# TC37XPD register map
Vendor: Infineon; Series: ATVMC; File version: 100
CPU: other r0p0, little endian, MPU, FPU, vendor SysTick, 4 interrupt priority bits
Registers are 32-bit, read-write, reset 0x0 unless marked. A register's access mark holds for its fields unless they carry their own. Offsets are from the block's base; [hi:lo] are bit positions; {n}, {i} and the like mark numbered series; 'fields as' and 'values as' point back to an identical list.

## GETH (part 1 of 7)
Base 0xF001D000
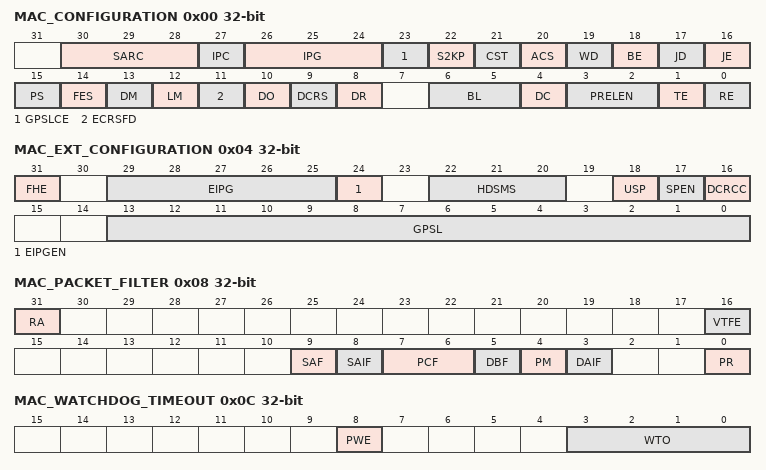
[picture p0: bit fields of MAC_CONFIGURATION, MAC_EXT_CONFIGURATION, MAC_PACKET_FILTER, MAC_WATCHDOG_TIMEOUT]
0x00 MAC_CONFIGURATION — MAC Configuration Register resetvalue={Application Reset:0x0}
  [30:28] SARC — Source Address Insertion or Replacement Control SARC. This field controls the source address insertion or replacement for all transmitted packets. Bit 30 specifies which MAC Address register 0 or 1 is used for source address insertion or replacement based on the values of Bits 29 28 Note Changes to this field take effect only on the start of a packet. If you write to this register field when a packet is being transmitted only the subsequent packet can use the updated value that is the current packet does not use the updated value. Value After Reset 0x0
  [27] IPC — Checksum Offload IPC. When set this bit enables the IPv4 header checksum checking and IPv4 or IPv6 TCP UDP or ICMP payload checksum checking. When this bit is reset the COE function in the receiver is disabled. The Layer 3 and Layer 4 Packet Filter and Enable Split Header features automatically selects the IPC Full Checksum Offload Engine on the Receive side. When any of these features are enabled you must set the IPC bit. Value After Reset 0x0
  [26:24] IPG — Inter Packet Gap IPG. These bits control the minimum IPG between packets during transmission. LOST SEQUENCE DEFINITION This range of minimum IPG is valid in full duplex mode. In the half duplex mode the minimum IPG can be configured only for 64 bit times IPG 100 . Lower values are not considered. When a JAM pattern is being transmitted because of backpressure activation the MAC does not consider the minimum IPG. The above function IPG less than 96 bit times is valid only when EIPGEN bit in MAC Ext Configuration register is reset. When EIPGEN is set then the minimum IPG greater than 96 bit times is controlled as per the description given in EIPG field in MAC Ext Configuration register. Value After Reset 0x0
  [23] GPSLCE — Giant Packet Size Limit Control Enable GPSLCE. When this bit is set the MAC considers the value in GPSL field in MAC Ext Configuration register to declare a received packet as Giant packet. This field must be programmed to more than 1 518 bytes. Otherwise the MAC considers 1 518 bytes as giant packet limit. When this bit is reset the MAC considers a received packet as Giant packet when its size is greater than 1 518 bytes 1522 bytes for tagged packet . The watchdog timeout limit Jumbo Packet Enable and 2K Packet Enable have higher precedence over this bit that is the MAC considers a received packet as Giant packet when its size is greater than 9 018 bytes 9 022 bytes for tagged packet with Jumbo Packet Enabled and greater than 2 000 bytes with 2K Packet Enabled. The watchdog timeout if enabled terminates the received packet when watchdog limit is reached. Therefore the programmed giant packet limit should be less than the watchdog limit to get the giant packet status. Value After Reset 0x0
  [22] S2KP — IEEE 802.3as Support for 2K Packets S2KP. When this bit is set the MAC considers all packets with up to 2 000 bytes length as normal packets. When the JE bit is not set the MAC considers all received packets of size more than 2K bytes as Giant packets. When this bit is reset and the JE bit is not set the MAC considers all received packets of size more than 1 518 bytes 1 522 bytes for tagged as giant packets. For more information about how the setting of this bit and the JE bit impact the Giant packet status see the table Giant Packet Status based on S2KP and JE Bits. Note When the JE bit is set setting this bit has no effect on the giant packet status. Value After Reset 0x0
  [21] CST — CRC stripping for Type packets CST. When this bit is set the last four bytes FCS of all packets of Ether type type field greater than 1 536 are stripped and dropped before forwarding the packet to the application. Note For information about how the settings of the ACS bit and this bit impact the packet length see the Table Packet Length based on the CST and ACS Bits. Value After Reset 0x0
  [20] ACS — Automatic Pad or CRC Stripping ACS. When this bit is set the MAC strips the Pad or FCS field on the incoming packets only if the value of the length field is less than 1 536 bytes. All received packets with length field greater than or equal to 1 536 bytes are passed to the application without stripping the Pad or FCS field. When this bit is reset the MAC passes all incoming packets to the application without any modification. Note For information about how the settings of CST bit and this bit impact the packet length see the Table Packet Length based on the CST and ACS Bit . Value After Reset 0x0
  [19] WD — Watchdog Disable WD. When this bit is set the MAC disables the watchdog timer on the receiver. The MAC can receive packets of up to 16 383 bytes. When this bit is reset the MAC does not allow more than 2 048 bytes 10 240 if JE is set high of the packet being received. The MAC cuts off any bytes received after 2 048 bytes. Value After Reset 0x0
  [18] BE — Packet Burst Enable BE. When this bit is set the MAC allows packet bursting during transmission in the GMII half duplex mode. Value After Reset 0x0
  [17] JD — Jabber Disable JD. When this bit is set the MAC disables the jabber timer on the transmitter. The MAC can transfer packets of up to 16 383 bytes. When this bit is reset if the application sends more than 2 048 bytes of data 10 240 if JE is set high during transmission the MAC does not send rest of the bytes in that packet. Value After Reset 0x0
  [16] JE — Jumbo Packet Enable JE. When this bit is set the MAC allows jumbo packets of 9 018 bytes 9 022 bytes for VLAN tagged packets without reporting a giant packet error in the Rx packet status. Value After Reset 0x0
  [15] PS — Port Select PS. This bit selects the Ethernet line speed. This bit along with Bit 14 selects the exact line speed. In the 10 100 Mbps only always 1 or 1000 Mbps only always 0 configurations this bit is read only RO with appropriate value. In default 10 100 1000 Mbps configurations this bit is read write R W . The mac speed o 1 signal reflects the value of this bit. Value After Reset 0x0
  [14] FES — Speed FES. This bit selects the speed mode The mac speed o 0 signal reflects the value of this bit. Value After Reset 0x0
  [13] DM — Duplex Mode DM. When this bit is set the MAC operates in the full duplex mode in which it can transmit and receive simultaneously. Value After Reset 0x0
  [12] LM — Loopback Mode LM. When this bit is set the MAC operates in the loopback mode at GMII or MII. The G MII Rx clock input clk rx i is required for the loopback to work properly. This is because the Tx clock is not internally looped back. Value After Reset 0x0
  [11] ECRSFD — Enable Carrier Sense Before Transmission in Full Duplex Mode ECRSFD. When this bit is set the MAC transmitter checks the CRS signal before packet transmission in the full duplex mode. The MAC starts the transmission only when the CRS signal is low. When this bit is reset the MAC transmitter ignores the status of the CRS signal. Value After Reset 0x0
  [10] DO — Disable Receive Own DO. When this bit is set the MAC disables the reception of packets when the gmii txen o is asserted in the half duplex mode. When this bit is reset the MAC receives all packets given by the PHY. Value After Reset 0x0
  [9] DCRS — Disable Carrier Sense During Transmission DCRS. When this bit is set the MAC transmitter ignores the G MII CRS signal during packet transmission in the half duplex mode. As a result no errors are generated because of Loss of Carrier or No Carrier during transmission. When this bit is reset the MAC transmitter generates errors because of Carrier Sense. The MAC can even abort the transmission. Value After Reset 0x0
  [8] DR — Disable Retry DR. When this bit is set the MAC attempts only one transmission. When a collision occurs on the GMII or MII interface the MAC ignores the current packet transmission and reports a Packet Abort with excessive collision error in the Tx packet status. When this bit is reset the MAC retries based on the settings of the BL field. Value After Reset 0x0
  [6:5] BL — Back Off Limit BL. The back off limit determines the random integer number r of slot time delays 4 096 bit times for 1000 2500 Mbps 512 bit times for 10 100 Mbps for which the MAC waits before rescheduling a transmission attempt during retries after a collision. where n retransmission attempt The random integer r takes the value in the range 0 lt r lt 2 k Value After Reset 0x0
  [4] DC — Deferral Check DC. When this bit is set the deferral check function is enabled in the MAC. The MAC issues a Packet Abort status along with the excessive deferral error bit set in the Tx packet status when the Tx state machine is deferred for more than 24 288 bit times in 10 or 100 Mbps mode. If the MAC is configured for 1000 2500 Mbps operation the threshold for deferral is 155 680 bits times. Deferral begins when the transmitter is ready to transmit but it is prevented because of an active carrier sense signal CRS on GMII or MII. The defer time is not cumulative. For example if the transmitter defers for 10 000 bit times because the CRS signal is active and the CRS signal becomes inactive the transmitter transmits and collision happens. Because of collision the transmitter needs to back off and then defer again after back off completion. In such a scenario the deferral timer is reset to 0 and it is restarted. When this bit is reset the deferral check function is disabled and the MAC defers until the CRS signal goes inactive. Value After Reset 0x0
  [3:2] PRELEN — Preamble Length for Transmit packets PRELEN. These bits control the number of preamble bytes that are added to the beginning of every Tx packet. The preamble reduction occurs only when the MAC is operating in the full duplex mode. Value After Reset 0x0
  [1] TE — Transmitter Enable TE. When this bit is set the Tx state machine of the MAC is enabled for transmission on the GMII or MII interface. When this bit is reset the MAC Tx state machine is disabled after it completes the transmission of the current packet. The Tx state machine does not transmit any more packets. Value After Reset 0x0
  [0] RE — Receiver Enable RE. When this bit is set the Rx state machine of the MAC is enabled for receiving packets from the GMII or MII interface. When this bit is reset the MAC Rx state machine is disabled after it completes the reception of the current packet. The Rx state machine does not receive any more packets from the GMII or MII interface. Value After Reset 0x0
0x04 MAC_EXT_CONFIGURATION — MAC Extended Configuration Register resetvalue={Application Reset:0x0}
  [31] FHE — Flexible Header Enable. When this is set then it is expected that all the incoming packets from the Line to have 4B Flexible Header in the Rx path except for the pause and PFC packets . Similarly in the Tx path all the packets from application are expected to have 4B Flexible header. The position of the Flexible Header is always fixed at 12Bytes from the beginning of the packet after MAC DA SA .
  [29:25] EIPG — Extended Inter Packet Gap EIPG. The value in this field is applicable when the EIPGEN bit is set. This field as Most Significant bits along with IPG field in MAC Configuration register gives the minimum IPG greater than 96 bit times in steps of 8 bit times EIPG IPG 8 h00 104 bit times 8 h01 112 bit times 8 h02 120 bit times 8 hFF 2144 bit times Value After Reset 0x0
  [24] EIPGEN — Extended Inter Packet Gap Enable EIPGEN. When this bit is set the MAC interprets EIPG field and IPG field in MAC Configuration register together as minimum IPG greater than 96 bit times in steps of 8 bit times. When this bit is reset the MAC ignores EIPG field and interprets IPG field in MAC Configuration register as minimum IPG less than or equal to 96 bit times in steps of 8 bit times. Note The extended Inter Packet Gap feature must be enabled when operating in Full Duplex mode only. There may be undesirable effects on back pressure function and frame transmission if it is enabled in Half Duplex mode. Value After Reset 0x0
  [22:20] HDSMS — Maximum Size for Splitting the Header Data HDSMS. These bits indicate the maximum header size allowed for splitting the header data in the received packet 101 111 Reserved If the Enable Split Header Structure option is not selected these bits are reserved and read only RO . Value After Reset 0x0
  [18] USP — Unicast Slow Protocol Packet Detect USP. When this bit is set the MAC detects the Slow Protocol packets with unicast address of the station specified in the MAC Address0 High and MAC Address0 Low registers. The MAC also detects the Slow Protocol packets with the Slow Protocols multicast address 01 80 C2 00 00 02 . When this bit is reset the MAC detects only Slow Protocol packets with the Slow Protocol multicast address specified in the IEEE 802.3 2008 Section 5. Value After Reset 0x0
  [17] SPEN — Slow Protocol Detection Enable SPEN. When this bit is set MAC processes the Slow Protocol packets Ether Type 0x8809 and provides the Rx status. The MAC discards the Slow Protocol packets with invalid sub types. When this bit is reset the MAC forwards all error free Slow Protocol packets to the application. The MAC considers such packets as normal Type packets. Value After Reset 0x0
  [16] DCRCC — Disable CRC Checking for Received Packets DCRCC. When this bit is set the MAC receiver does not check the CRC field in the received packets. When this bit is reset the MAC receiver always checks the CRC field in the received packets. Value After Reset 0x0
  [13:0] GPSL — Giant Packet Size Limit GPSL. If the received packet size is greater than the value programmed in this field in units of bytes the MAC declares the received packet as Giant packet. The value programmed in this field must be greater than or equal to 1 518 bytes. Any other programmed value is considered as 1 518 bytes. For VLAN tagged packets the MAC adds 4 bytes to the programmed value. When the Enable Double VLAN Processing option is selected the MAC adds 8 bytes to the programmed value for double VLAN tagged packets. The value in this field is applicable when the GPSLCE bit is set in MAC Configuration register. Value After Reset 0x0
0x08 MAC_PACKET_FILTER — MAC Packet Filter Register resetvalue={Application Reset:0x0}
  [31] RA — Receive All RA. When this bit is set the MAC Receiver module passes all received packets to the application irrespective of whether they pass the address filter or not. The result of the SA or DA filtering is updated pass or fail in the corresponding bit in the Rx Status Word. When this bit is reset the Receiver module passes only those packets to the application that pass the SA or DA address filter. Value After Reset 0x0
  [16] VTFE — VLAN Tag Filter Enable VTFE. When this bit is set the MAC drops the VLAN tagged packets that do not match the VLAN Tag. When this bit is reset the MAC forwards all packets irrespective of the match status of the VLAN Tag. Value After Reset 0x0
  [9] SAF — Source Address Filter Enable SAF. When this bit is set the MAC compares the SA field of the received packets with the values programmed in the enabled SA registers. If the comparison fails the MAC drops the packet. When this bit is reset the MAC forwards the received packet to the application with updated SAF bit of the Rx Status depending on the SA address comparison. Note According to the IEEE specification Bit 47 of the SA is reserved. However in DWC ether qos the MAC compares all 48 bits. The software driver should take this into consideration while programming the MAC address registers for SA. Value After Reset 0x0
  [8] SAIF — SA Inverse Filtering SAIF. When this bit is set the Address Check block operates in the inverse filtering mode for SA address comparison. If the SA of a packet matches the values programmed in the SA registers it is marked as failing the SA Address filter. When this bit is reset if the SA of a packet does not match the values programmed in the SA registers it is marked as failing the SA Address filter. Value After Reset 0x0
  [7:6] PCF — Pass Control Packets PCF. These bits control the forwarding of all control packets including unicast and multicast Pause packets . Value After Reset 0x0
  [5] DBF — Disable Broadcast Packets DBF. When this bit is set the AFM module blocks all incoming broadcast packets. In addition it overrides all other filter settings. When this bit is reset the AFM module passes all received broadcast packets. Value After Reset 0x0
  [4] PM — Pass All Multicast PM. When this bit is set it indicates that all received packets with a multicast destination address first bit in the destination address field is 1 are passed. Value After Reset 0x0
  [3] DAIF — DA Inverse Filtering DAIF. When this bit is set the Address Check block operates in inverse filtering mode for the DA address comparison for both unicast and multicast packets. When this bit is reset normal filtering of packets is performed. Value After Reset 0x0
  [0] PR — Promiscuous Mode PR. When this bit is set the Address Filtering module passes all incoming packets irrespective of the destination or source address. The SA or DA Filter Fails status bits of the Rx Status Word are always cleared when PR is set. Value After Reset 0x0
0x0C MAC_WATCHDOG_TIMEOUT — MAC Watchdog Timeout Register resetvalue={Application Reset:0x0}
  [8] PWE — Programmable Watchdog Enable PWE. When this bit is set and the WD bit of the MAC Configuration register is reset the WTO field is used as watchdog timeout for a received packet. When this bit is cleared the watchdog timeout for a received packet is controlled by setting of WD and JE bits in MAC Configuration register. Value After Reset 0x0
  [3:0] WTO — Watchdog Timeout WTO. When the PWE bit is set and the WD bit of the MAC Configuration register is reset this field is used as watchdog timeout for a received packet. If the length of a received packet exceeds the value of this field such packet is terminated and declared as an error packet. Encoding is as follows LOST SEQUENCE DEFINITION Note When the PWE bit is set the value in this field should be more than 1 522 0x05F2 . Otherwise the IEEE 802.3 specified valid tagged packets are declared as error packets and then dropped. Value After Reset 0x0
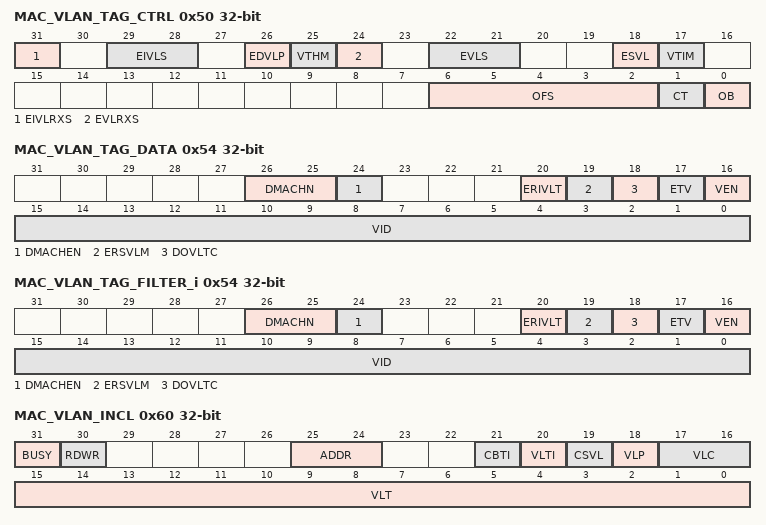
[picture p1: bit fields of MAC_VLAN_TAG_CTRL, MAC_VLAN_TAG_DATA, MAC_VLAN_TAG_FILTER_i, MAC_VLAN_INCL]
0x50 MAC_VLAN_TAG_CTRL — MAC VLAN Tag Control Register resetvalue={Application Reset:0x0}
  [31] EIVLRXS — Enable Inner VLAN Tag in Rx Status EIVLRXS. When this bit is set the MAC provides the inner VLAN Tag in the Rx status. When this bit is reset the MAC does not provide the inner VLAN Tag in Rx status. Value After Reset 0x0
  [29:28] EIVLS — Enable Inner VLAN Tag Stripping on Receive EIVLS. This field indicates the stripping operation on inner VLAN Tag in received packet Value After Reset 0x0
  [26] EDVLP — Enable Double VLAN Processing EDVLP. When this bit is set the MAC enables processing of up to two VLAN Tags on Tx and Rx if present . When this bit is reset the MAC enables processing of up to one VLAN Tag on Tx and Rx if present . Value After Reset 0x0
  [25] VTHM — VLAN Tag Hash Table Match Enable VTHM. When this bit is set the most significant four bits of CRC of VLAN Tag ones complement of most significant four bits of CRC of VLAN Tag when ETV bit is reset are used to index the content of the MAC VLAN Hash Table register. A value of 1 in the VLAN Hash Table register corresponding to the index indicates that the packet matched the VLAN hash table. When the ETV bit is set the CRC of the 12 bit VLAN Identifier VID is used for comparison. When the ETV bit is reset the ones complement of the CRC of the 16 bit VLAN tag is used for comparison. When this bit is reset the VLAN Hash Match operation is not performed. Value After Reset 0x0
  [24] EVLRXS — Enable VLAN Tag in Rx status EVLRXS. When this bit is set MAC provides the outer VLAN Tag in the Rx status. When this bit is reset the MAC does not provide the outer VLAN Tag in Rx status. Value After Reset 0x0
  [22:21] EVLS — Enable VLAN Tag Stripping on Receive EVLS. This field indicates the stripping operation on the outer VLAN Tag in received packet Value After Reset 0x0
  [18] ESVL — Enable S VLAN ESVL. When this bit is set the MAC transmitter and receiver consider the S VLAN packets Type 0x88A8 as valid VLAN tagged packets. Value After Reset 0x0
  [17] VTIM — VLAN Tag Inverse Match Enable VTIM. When this bit is set this bit enables the VLAN Tag inverse matching. The packets without matching VLAN Tag are marked as matched. When reset this bit enables the VLAN Tag perfect matching. The packets with matched VLAN Tag are marked as matched. Value After Reset 0x0
  [6:2] OFS — Offset OFS. This field holds the address offset of the MAC VLAN Tag Filter Register which the application is trying to access. The width of the field depends on the number of MAC VLAN Tag Registers enabled. Value After Reset 0x0
  [1] CT — Command Type CT. This bit indicates if the current register access is a read or a write. When set it indicate a read operation. When reset it indicates a write operation. Value After Reset 0x0
  [0] OB — Operation Busy OB. This bit is set along with a read or write command for initiating the indirect access to per VLAN Tag Filter register. This bit is reset when the read or write command to per VLAN Tag Filter indirect access register is complete.The next indirect register access can be initiated only after this bit is reset. During a write operation the bit is reset only after the data has been written into the Per VLAN Tag register. During a read operation the data should be read from the MAC VLAN Tag Data register only after this bit is reset. Value After Reset 0x0
0x54 MAC_VLAN_TAG_DATA — MAC VLAN Tag Data Register resetvalue={Application Reset:0x0}
  [26:25] DMACHN — DMA Channel Number DMACHN. The DMA Channel number to which the VLAN Tagged Frame is to be routed if it passes this VLAN Tag Filter is programmed in this field. If the Routing based on VLAN Tag Filter is not necessary this field need not be programmed. Value After Reset 0x0
  [24] DMACHEN — DMA Channel Number Enable DMACHEN. This bit is the Enable for the DMA Channel Number value programmed in the field DMACH. When this bit is reset the Routing does not occur based on VLAN Filter result. The frame is routed based on DA Based DMA Channel Routing. Value After Reset 0x0
  [20] ERIVLT — Enable Inner VLAN Tag Comparison ERIVLT. This bit is valid only when VLAN Tag Enable of the Filter is set. When this bit and the EDVLP field are set the MAC receiver enables operation on the inner VLAN Tag if present . When this bit is reset the MAC receiver enables operation on the outer VLAN Tag if present . Value After Reset 0x0
  [19] ERSVLM — Enable S VLAN Match for received Frames ERSVLM. This bit is valid only when VLAN Tag Enable of the Filter is set. When this bit is set the MAC receiver enables filtering or matching for S VLAN Type 0x88A8 packets. When this bit is reset the MAC receiver enables filtering or matching for C VLAN Type 0x8100 packets. Value After Reset 0x0
  [18] DOVLTC — Disable VLAN Type Comparison DOVLTC. This bit is valid only when VLAN Tag Enable of the Filter is set. When this bit is set the MAC does not check whether the VLAN Tag specified by the Enable Inner VLAN Tag Comparison bit is of type S VLAN or C VLAN. When this bit is reset the MAC filters or matches the VLAN Tag specified by the Enable Inner VLAN Tag Comparison bit only when VLAN Tag type is similar to the one specified by the Enable S VLAN Match for received Frames bit. Value After Reset 0x0
  [17] ETV — 12bits or 16bits VLAN comparison ETV. This bit is valid only when VEN of the Filter is set. When this bit is set a 12 bit VLAN identifier is used for comparing and filtering instead of the complete 16 bit VLAN tag. Bits 11 0 of VLAN tag are compared with the corresponding field in the received VLAN tagged packet. Value After Reset 0x0
  [16] VEN — VLAN Tag Enable VEN. This bit is used to enable or disable the VLAN Tag. When this bit is set the MAC compares the VLAN Tag of received packet with the VLAN Tag ID. When this bit is reset no comparison is performed irrespective of the programming of the other fields. Value After Reset 0x0
  [15:0] VID — VLAN Tag ID VID. This field holds the VLAN Tag value which is used by the MAC for perfect comparison. It is valid when VLAN Tag Enable is set. Value After Reset 0x0
0x54 MAC_VLAN_TAG_FILTER_i (alternate view of MAC_VLAN_TAG_DATA) — MAC VLAN Tag Filter Register resetvalue={Application Reset:0x0}
  fields as MAC_VLAN_TAG_DATA
0x58 MAC_VLAN_HASH_TABLE — MAC VLAN Hash Table Register resetvalue={Application Reset:0x0}
  [15:0] VLHT — VLAN Hash Table VLHT. This field contains the 16 bit VLAN Hash Table. Value After Reset 0x0
0x60 MAC_VLAN_INCL access per field — MAC VLAN Tag Inclusion or Replacement Register resetvalue={Application Reset:0x0}
  [31] BUSY ro — Busy BUSY. Value After Reset 0x0
  [30] RDWR rw — Read write control RDWR. This bit controls the read or write operation for indirectly accessing the queue channel specific VLAN Inclusion register. When set indicates write operation and when reset indicates read operation This doesn 8217 t have any effect when CBTI is reset Value After Reset 0x0
  [25:24] ADDR rw — Address ADDR. This field selects one of the queue channel specific VLAN Inclusion register for read write access This doesn 8217 t have any effect when CBTI is reset Value After Reset 0x0
  [21] CBTI rw — Channel based tag insertion CBTI. When this bit is set outer VLAN tag is inserted for every packets transmitted by the MAC. The tag value is taken from the queue channel specific VLAN tag register. The VLTI VLP VLC and VLT fields of this register are ignored when this bit is set. When this bit is set a write operation to byte 3 of this register initiates the read write access to the indirect register. When reset outer VLAN operation is based on the setting of VLTI VLP VLC and VLT fields of this register Value After Reset 0x0
  [20] VLTI rw — VLAN Tag Input VLTI. When this bit is set it indicates that the VLAN tag to be inserted or replaced in Tx packet should be taken from The Tx descriptor Value After Reset 0x0
  [19] CSVL rw — C VLAN or S VLAN CSVL. When this bit is set S VLAN type 0x88A8 is inserted or replaced in the 13th and 14th bytes of transmitted packets. When this bit is reset C VLAN type 0x8100 is inserted or replaced in the 13th and 14th bytes of transmitted packets. Value After Reset 0x0
  [18] VLP rw — VLAN Priority Control VLP. When this bit is set the control bits 17 16 are used for VLAN deletion insertion or replacement. When this bit is reset the mti vlan ctrl i control input is used and bits 17 16 are ignored. Value After Reset 0x0
  [17:16] VLC rw — VLAN Tag Control in Transmit Packets VLC. Note Changes to this field take effect only on the start of a packet. If you write this register field when a packet is being transmitted only the subsequent packet can use the updated value that is the current packet does not use the updated value. Value After Reset 0x0
  [15:0] VLT rw — VLAN Tag for Transmit Packets VLT. This field contains the value of the VLAN tag to be inserted or replaced. The value must only be changed when the transmit lines are inactive or during the initialization phase. Bits 15 13 are the User Priority field Bit 12 is the CFI DEI field and Bits 11 0 are the VID field in the VLAN tag. The following list describes the bits of this field Bits 15 13 User Priority Bit 12 Canonical Format Indicator CFI or Drop Eligible Indicator DEI Bits 11 0 VLAN Identifier VID field of VLAN tag Value After Reset 0x0
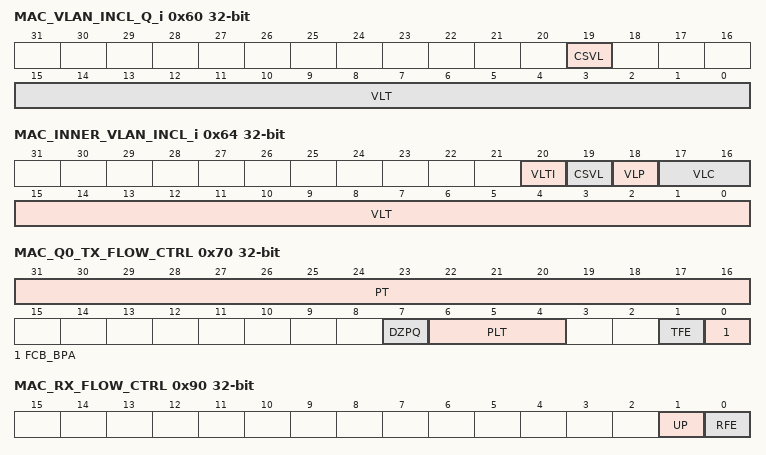
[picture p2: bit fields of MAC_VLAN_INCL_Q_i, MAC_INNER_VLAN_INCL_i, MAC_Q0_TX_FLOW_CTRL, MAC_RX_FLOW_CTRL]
0x60 MAC_VLAN_INCL_Q_i (alternate view of MAC_VLAN_INCL) — MAC VLAN Tag Inclusion or Replacement Register per Queue resetvalue={Application Reset:0x0}
  [19] CSVL — C VLAN or S VLAN CSVL. When this bit is set S VLAN type 0x88A8 is inserted in the 13th and 14th bytes of transmitted packets. When this bit is reset C VLAN type 0x8100 is inserted in the 13th and 14th bytes of transmitted packets. Value After Reset 0x0
  [15:0] VLT — VLAN Tag for Transmit Packets VLT. This field contains the value of the VLAN tag to be inserted. The value must only be changed when the transmit lines are inactive or during the initialization phase. Bits 15 13 are the User Priority field Bit 12 is the CFI DEI field and Bits 11 0 are the VID field in the VLAN tag. The following list describes the bits of this field Bits 15 13 User Priority Bit 12 Canonical Format Indicator CFI or Drop Eligible Indicator DEI Bits 11 0 VLAN Identifier VID field of VLAN tag Value After Reset 0x0
0x64 MAC_INNER_VLAN_INCL_i — MAC Inner VLAN Tag Inclusion or Replacement Register resetvalue={Application Reset:0x0}
  [20] VLTI — VLAN Tag Input VLTI. When this bit is set it indicates that the VLAN tag to be inserted or replaced in Tx packet should be taken from The Tx descriptor Value After Reset 0x0
  [19] CSVL — C VLAN or S VLAN CSVL. When this bit is set S VLAN type 0x88A8 is inserted or replaced in the 13th and 14th bytes of transmitted packets. When this bit is reset C VLAN type 0x8100 is inserted or replaced in the 13th and 14th bytes of transmitted packets. Value After Reset 0x0
  [18] VLP — VLAN Priority Control VLP. When this bit is set the VLC field is used for VLAN deletion insertion or replacement. When this bit is reset the mti vlan ctrl i control input is used and the VLC field is ignored. Value After Reset 0x0
  [17:16] VLC — VLAN Tag Control in Transmit Packets VLC. The MAC removes the VLAN type bytes 17 and 18 and VLAN tag bytes 19 and 20 of all transmitted packets with VLAN tags. The MAC inserts VLT in bytes 19 and 20 of the packet after inserting the Type value 0x8100 or 0x88a8 in bytes 17 and 18. This operation is performed on all transmitted packets irrespective of whether they already have a VLAN tag. The MAC replaces VLT in bytes 19 and 20 of all VLAN type transmitted packets Bytes 17 and 18 are 0x8100 or 0x88a8 . Note Changes to this field take effect only on the start of a packet. If you write this register field when a packet is being transmitted only the subsequent packet can use the updated value that is the current packet does not use the updated value. Value After Reset 0x0
  [15:0] VLT — VLAN Tag for Transmit Packets VLT. This field contains the value of the VLAN tag to be inserted or replaced. The value must only be changed when the transmit lines are inactive or during the initialization phase. Bits 15 13 are the User Priority field Bit 12 is the CFI DEI field and Bits 11 0 are the VID field in the VLAN tag. The following list describes the bits of this field Bits 15 13 User Priority Bit 12 Canonical Format Indicator CFI or Drop Eligible Indicator DEI Bits 11 0 VLAN Identifier VID field of VLAN tag Value After Reset 0x0
0x70 MAC_Q0_TX_FLOW_CTRL — MAC Queue 0 TX Flow Control Register resetvalue={Application Reset:0x0}
  [31:16] PT — Pause Time PT. This field holds the value to be used in the Pause Time field in the Tx control packet. If the Pause Time bits are configured to be double synchronized to the G MII clock domain consecutive writes to this register should be performed only after at least four clock cycles in the destination clock domain. Value After Reset 0x0
  [7] DZPQ — Disable Zero Quanta Pause DZPQ. When this bit is set it disables the automatic generation of the zero quanta Pause packets on de assertion of the flow control signal from the FIFO layer MTL or external sideband flow control signal sbd flowctrl i or mti flowctrl i . When this bit is reset normal operation with automatic zero quanta Pause packet generation is enabled. Value After Reset 0x0
  [6:4] PLT — Pause Low Threshold PLT. This field configures the threshold of the Pause timer at which the input flow control signal mti flowctrl i or sbd flowctrl i is checked for automatic retransmission of the Pause packet. The threshold values should be always less than the Pause Time configured in Bits 31 16 . For example if PT 100H 256 slot times and PLT 001 a second Pause packet is automatically transmitted if the mti flowctrl i signal is asserted at 228 256 28 slot times after the first Pause packet is transmitted. The following list provides the threshold values for different values 110 111 Reserved The slot time is defined as the time taken to transmit 512 bits 64 bytes on the GMII or MII interface. This approximate computation is based on the packet size 64 1518 2000 9018 16384 or 32768 2 Pause Packet Size IPG in Slot Times. Value After Reset 0x0
  [1] TFE — Transmit Flow Control Enable TFE. Full Duplex Mode In the full duplex mode when this bit is set the MAC enables the flow control operation to Tx Pause packets. When this bit is reset the flow control operation in the MAC is disabled and the MAC does not transmit any Pause packets. Half Duplex Mode In the half duplex mode when this bit is set the MAC enables the backpressure operation. When this bit is reset the backpressure feature is disabled. Value After Reset 0x0
  [0] FCB_BPA — Flow Control Busy or Backpressure Activate FCB BPA. This bit initiates a Pause packet in the full duplex mode and activates the backpressure function in the half duplex mode if the TFE bit is set. Full Duplex Mode In the full duplex mode this bit should be read as 1 b0 before writing to this register. To initiate a Pause packet the application must set this bit to 1 b1. During Control packet transfer this bit continues to be set to indicate that a packet transmission is in progress. When Pause packet transmission is complete the MAC resets this bit to 1 b0. You should not write to this register until this bit is cleared. Half Duplex Mode When this bit is set and TFE bit is set in the half duplex mode the MAC asserts the backpressure. During backpressure when the MAC receives a new packet the transmitter starts sending a JAM pattern resulting in a collision. This control register bit is logically ORed with the mti flowctrl i input signal for the backpressure function. When the MAC is configured for the full duplex mode the BPA is automatically disabled. Access restriction applies. Setting 1 sets. Self cleared. Setting 0 has no effect. Value After Reset 0x0
0x90 MAC_RX_FLOW_CTRL — MAC Receive Flow Control Register resetvalue={Application Reset:0x0}
  [1] UP — Unicast Pause Packet Detect UP. A pause packet is processed when it has the unique multicast address specified in the IEEE 802.3. When this bit is set the MAC can also detect Pause packets with unicast address of the station. This unicast address should be as specified in MAC Address0 High and MAC Address0 Low. When this bit is reset the MAC only detects Pause packets with unique multicast address. Note The MAC does not process a Pause packet if the multicast address is different from the unique multicast address. This is also applicable to the received PFC packet when the Priority Flow Control PFC is enabled. The unique multicast address 0x01 80 C2 00 00 01 is as specified in IEEE 802.1 Qbb 2011. Value After Reset 0x0
  [0] RFE — Receive Flow Control Enable RFE. When this bit is set and the MAC is operating in full duplex mode the MAC decodes the received Pause packet and disables its transmitter for a specified Pause time. When this bit is reset or the MAC is operating in half duplex mode the decode function of the Pause packet is disabled. When PFC is enabled flow control is enabled for PFC packets. The MAC decodes the received PFC packet and disables the Transmit queue with matching priorities for a duration of received Pause time. Value After Reset 0x0
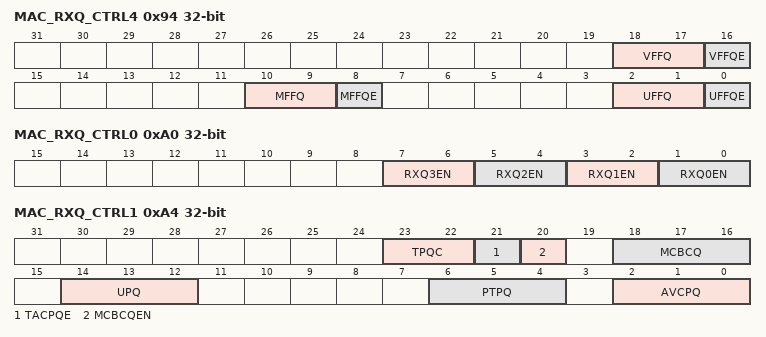
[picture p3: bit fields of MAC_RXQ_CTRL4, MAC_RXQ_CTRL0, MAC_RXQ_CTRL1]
0x94 MAC_RXQ_CTRL4 — MAC Receive Queue Control 4 register resetvalue={Application Reset:0x0}
  [18:17] VFFQ — VLAN Tag Filter Fail Packets Queue VFFQ. This field holds the Rx queue number to which the tagged packets failing the Destination or Source Address filter and UFFQE MFFQE not enabled or failing the VLAN tag filter must be routed to. This field is valid only when the VFFQE bit is set. Value After Reset 0x0
  [16] VFFQE — VLAN Tag Filter Fail Packets Queuing Enable VFFQE. When this bit is set the tagged packets which fail the Destination or Source address filter or fail the VLAN tag filter are routed to the Rx Queue Number programmed in the VFFQ. When this bit is reset the tagged packets which fail the Destination or Source address filter or fail the VLAN tag filter are routed based on other routing options. This bit is valid only when the RA bit of the MAC Packet Filter register is set.
  [10:9] MFFQ — Multicast Address Filter Fail Packets Queue MFFQ. This field holds the Rx queue number to which the Multicast packets failing the Destination or Source Address filter are routed to. This field is valid only when the MFFQE bit is set. Value After Reset 0x0
  [8] MFFQE — Multicast Address Filter Fail Packets Queuing Enable MFFQE. When this bit is set the Multicast packets which fail the Destination or Source address filter is routed to the Rx Queue Number programmed in the MFFQ. When this bit is reset the Multicast packets which fail the Destination or Source address filter is routed based on other routing options. This bit is valid only when the RA bit of the MAC Packet Filter register is set. Value After Reset 0x0
  [2:1] UFFQ — Unicast Address Filter Fail Packets Queue UFFQ. This field holds the Rx queue number to which the Unicast packets failing the Destination or Source Address filter are routed to. This field is valid only when the UFFQE bit is set. Value After Reset 0x0
  [0] UFFQE — Unicast Address Filter Fail Packets Queuing Enable UFFQE. When this bit is set the Unicast packets which fail the Destination or Source address filter is routed to the Rx Queue Number programmed in the UFFQ. When this bit is reset the Unicast packets which fail the Destination or Source address filter is routed based on other routing options. This bit is valid only when the RA bit of the MAC Packet Filter register is set. Value After Reset 0x0
0xA0 MAC_RXQ_CTRL0 — MAC Receive Queue Control 0 Register resetvalue={Application Reset:0x0}
  [7:6] RXQ3EN — Receive Queue 3 Enable RXQ3EN. This field is similar to the RXQ0EN field. Value After Reset 0x0
  [5:4] RXQ2EN — Receive Queue 2 Enable RXQ2EN. This field is similar to the RXQ0EN field. Value After Reset 0x0
  [3:2] RXQ1EN — Receive Queue 1 Enable RXQ1EN. This field is similar to the RXQ0EN field. Value After Reset 0x0
  [1:0] RXQ0EN — Receive Queue 0 Enable RXQ0EN. This field indicates whether Rx Queue 0 is enabled for AV or DCB. Value After Reset 0x0
0xA4 MAC_RXQ_CTRL1 — MAC Receive Queue Control 1 Register resetvalue={Application Reset:0x0}
  [23:22] TPQC — Tagged PTP over Ethernet Packets Queuing Control MFFQE. This field controls the routing of the VLAN Tagged PTPoE packets. The following programmable options are allowed. 8226 2 b00 VLAN Tagged PTPoE packets are routed as generic VLAN Tagged packet based on PSRQ for only non AV enabled Rx Queues . 8226 2 b01 VLAN Tagged PTPoE packets are routed to Rx Queue specified by PTPQ field That Rx Queue can be enabled for AV or non AV traffic . 8226 2 b10 VLAN Tagged PTPoE packets are routed to only AV enabled Rx Queues based on PSRQ. 8226 2 b11 Reserved Value After Reset 0x0
  [21] TACPQE — Tagged AV Control Packets Queuing Enable. TACPQE. When set the MAC routes the received Tagged AV Control packets to the Rx queue specified by AVCPQ field. When reset the MAC routes the received Tagged AV Control packets based on the tag priority matching the PSRQ fields in MAC RxQ Ctrl2 register. Value After Reset 0x0
  [20] MCBCQEN — Multicast and Broadcast Queue Enable MCBCQEN. This bit specifies that Multicast or Broadcast packets routing to the Rx Queue is enabled and the Multicast or Broadcast packets must be routed to Rx Queue specified in MCBCQ field. Value After Reset 0x0
  [18:16] MCBCQ — Multicast and Broadcast Queue MCBCQ. This field specifies the Rx Queue onto which Multicast or Broadcast Packets are routed. Any Rx Queue enabled for Generic DCB AV traffic can be used to route the Multicast or Broadcast Packets. LOST SEQUENCE DEFINITION Value After Reset 0x0
  [14:12] UPQ — Untagged Packet Queue UPQ. This field indicates the Rx Queue to which Untagged Packets are to be routed. Any Rx Queue enabled for Generic DCB AV traffic can be used to route the Untagged Packets. LOST SEQUENCE DEFINITION Value After Reset 0x0
  [6:4] PTPQ — PTP Packets Queue PTPQ. This field specifies the Rx queue on which the PTP packets sent over the Ethernet payload not over IPv4 or IPv6 are routed. When the AV8021ASMEN bit of MAC Timestamp Control register is set only untagged PTP over Ethernet packets are routed on an Rx Queue. If the bit is not set then based on programming of TPQC field both tagged and untagged PTPoE packets can be routed to this Rx Queue. Value After Reset 0x0
  [2:0] AVCPQ — AV Untagged Control Packets Queue AVCPQ. This field specifies the Receive queue on which the received AV tagged and untagged control packets are routed The AV tagged when TACPQE bit is set and untagged control packets are routed to Receive queue specified by this field. Value After Reset 0x0
